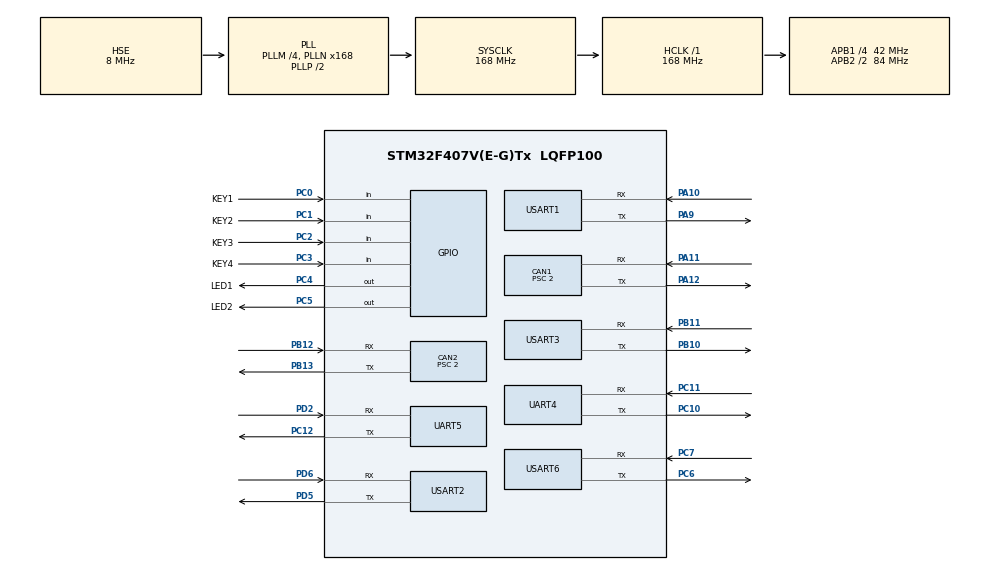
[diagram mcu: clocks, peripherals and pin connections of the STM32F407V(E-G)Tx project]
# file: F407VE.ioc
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CAN1.BS1=CAN_BS1_12TQ
CAN1.BS2=CAN_BS2_8TQ
CAN1.CalculateBaudRate=1000000
CAN1.CalculateTimeBit=1000
CAN1.CalculateTimeQuantum=47.61904761904762
CAN1.Prescaler=2
CAN1.SJW=CAN_SJW_1TQ
CAN2.BS1=CAN_BS1_12TQ
CAN2.BS2=CAN_BS2_8TQ
CAN2.CalculateBaudRate=1000000
CAN2.CalculateTimeBit=1000
CAN2.CalculateTimeQuantum=47.61904761904762
CAN2.Prescaler=2
CAN2.SJW=CAN_SJW_1TQ
Dma.Request0=USART3_RX
Dma.Request1=UART5_RX
Dma.Request2=USART3_TX
Dma.Request3=USART6_RX
Dma.Request4=USART1_RX
Dma.Request5=USART2_RX
Dma.Request6=UART4_RX
Dma.UART4_RX.6.Direction=DMA_PERIPH_TO_MEMORY
Dma.UART4_RX.6.FIFOMode=DMA_FIFOMODE_DISABLE
Dma.UART4_RX.6.Instance=DMA1_Stream2
Dma.UART4_RX.6.MemDataAlignment=DMA_MDATAALIGN_BYTE
Dma.UART4_RX.6.MemInc=DMA_MINC_ENABLE
Dma.UART4_RX.6.Mode=DMA_NORMAL
Dma.UART4_RX.6.PeriphDataAlignment=DMA_PDATAALIGN_BYTE
Dma.UART4_RX.6.PeriphInc=DMA_PINC_DISABLE
Dma.UART4_RX.6.Priority=DMA_PRIORITY_LOW
Dma.UART5_RX.1.Direction=DMA_PERIPH_TO_MEMORY
Dma.UART5_RX.1.FIFOMode=DMA_FIFOMODE_DISABLE
Dma.UART5_RX.1.Instance=DMA1_Stream0
Dma.UART5_RX.1.MemDataAlignment=DMA_MDATAALIGN_BYTE
Dma.UART5_RX.1.MemInc=DMA_MINC_ENABLE
Dma.UART5_RX.1.Mode=DMA_NORMAL
Dma.UART5_RX.1.PeriphDataAlignment=DMA_PDATAALIGN_BYTE
Dma.UART5_RX.1.PeriphInc=DMA_PINC_DISABLE
Dma.UART5_RX.1.Priority=DMA_PRIORITY_LOW
Dma.USART1_RX.4.Direction=DMA_PERIPH_TO_MEMORY
Dma.USART1_RX.4.FIFOMode=DMA_FIFOMODE_DISABLE
Dma.USART1_RX.4.Instance=DMA2_Stream2
Dma.USART1_RX.4.MemDataAlignment=DMA_MDATAALIGN_BYTE
Dma.USART1_RX.4.MemInc=DMA_MINC_ENABLE
Dma.USART1_RX.4.Mode=DMA_NORMAL
Dma.USART1_RX.4.PeriphDataAlignment=DMA_PDATAALIGN_BYTE
Dma.USART1_RX.4.PeriphInc=DMA_PINC_DISABLE
Dma.USART1_RX.4.Priority=DMA_PRIORITY_LOW
Dma.USART2_RX.5.Direction=DMA_PERIPH_TO_MEMORY
Dma.USART2_RX.5.FIFOMode=DMA_FIFOMODE_DISABLE
Dma.USART2_RX.5.Instance=DMA1_Stream5
Dma.USART2_RX.5.MemDataAlignment=DMA_MDATAALIGN_BYTE
Dma.USART2_RX.5.MemInc=DMA_MINC_ENABLE
Dma.USART2_RX.5.Mode=DMA_NORMAL
Dma.USART2_RX.5.PeriphDataAlignment=DMA_PDATAALIGN_BYTE
Dma.USART2_RX.5.PeriphInc=DMA_PINC_DISABLE
Dma.USART2_RX.5.Priority=DMA_PRIORITY_LOW
Dma.USART3_RX.0.Direction=DMA_PERIPH_TO_MEMORY
Dma.USART3_RX.0.FIFOMode=DMA_FIFOMODE_DISABLE
Dma.USART3_RX.0.Instance=DMA1_Stream1
Dma.USART3_RX.0.MemDataAlignment=DMA_MDATAALIGN_BYTE
Dma.USART3_RX.0.MemInc=DMA_MINC_ENABLE
Dma.USART3_RX.0.Mode=DMA_NORMAL
Dma.USART3_RX.0.PeriphDataAlignment=DMA_PDATAALIGN_BYTE
Dma.USART3_RX.0.PeriphInc=DMA_PINC_DISABLE
Dma.USART3_RX.0.Priority=DMA_PRIORITY_LOW
Dma.USART3_TX.2.Direction=DMA_MEMORY_TO_PERIPH
Dma.USART3_TX.2.FIFOMode=DMA_FIFOMODE_DISABLE
Dma.USART3_TX.2.Instance=DMA1_Stream3
Dma.USART3_TX.2.MemDataAlignment=DMA_MDATAALIGN_BYTE
Dma.USART3_TX.2.MemInc=DMA_MINC_ENABLE
Dma.USART3_TX.2.Mode=DMA_NORMAL
Dma.USART3_TX.2.PeriphDataAlignment=DMA_PDATAALIGN_BYTE
Dma.USART3_TX.2.PeriphInc=DMA_PINC_DISABLE
Dma.USART3_TX.2.Priority=DMA_PRIORITY_LOW
Dma.USART6_RX.3.Direction=DMA_PERIPH_TO_MEMORY
Dma.USART6_RX.3.FIFOMode=DMA_FIFOMODE_DISABLE
Dma.USART6_RX.3.Instance=DMA2_Stream1
Dma.USART6_RX.3.MemDataAlignment=DMA_MDATAALIGN_BYTE
Dma.USART6_RX.3.MemInc=DMA_MINC_ENABLE
Dma.USART6_RX.3.Mode=DMA_NORMAL
Dma.USART6_RX.3.PeriphDataAlignment=DMA_PDATAALIGN_BYTE
Dma.USART6_RX.3.PeriphInc=DMA_PINC_DISABLE
Dma.USART6_RX.3.Priority=DMA_PRIORITY_LOW
FREERTOS.Tasks01=defaultTask,24,128,StartDefaultTask,Default,NULL,Dynamic,NULL,NULL
FREERTOS.configTOTAL_HEAP_SIZE=16384
Mcu.Family=STM32F4
Mcu.Name=STM32F407V(E-G)Tx
Mcu.Package=LQFP100
NVIC.CAN1_RX0_IRQn=true\:5\:0\:false\:false\:true\:true\:true\:true\:true
NVIC.CAN1_RX1_IRQn=true\:5\:0\:false\:false\:true\:true\:true\:true\:true
NVIC.CAN2_RX0_IRQn=true\:5\:0\:false\:false\:true\:true\:true\:true\:true
NVIC.CAN2_RX1_IRQn=true\:5\:0\:false\:false\:true\:true\:true\:true\:true
NVIC.DMA1_Stream0_IRQn=true\:5\:0\:false\:false\:true\:true\:false\:true\:true
NVIC.DMA1_Stream1_IRQn=true\:5\:0\:false\:false\:true\:true\:false\:true\:true
NVIC.DMA1_Stream2_IRQn=true\:5\:0\:false\:false\:true\:true\:false\:true\:true
NVIC.DMA1_Stream3_IRQn=true\:5\:0\:false\:false\:true\:true\:false\:true\:true
NVIC.DMA1_Stream5_IRQn=true\:5\:0\:false\:false\:true\:true\:false\:true\:true
NVIC.DMA2_Stream1_IRQn=true\:5\:0\:false\:false\:true\:true\:false\:true\:true
NVIC.DMA2_Stream2_IRQn=true\:5\:0\:false\:false\:true\:true\:false\:true\:true
NVIC.PriorityGroup=NVIC_PRIORITYGROUP_4
NVIC.TIM3_IRQn=true\:5\:0\:false\:false\:true\:true\:true\:true\:true
NVIC.TIM8_TRG_COM_TIM14_IRQn=true\:15\:0\:false\:false\:true\:false\:false\:true\:true
NVIC.TimeBase=TIM8_TRG_COM_TIM14_IRQn
NVIC.TimeBaseIP=TIM14
NVIC.UART4_IRQn=true\:5\:0\:false\:false\:true\:true\:true\:true\:true
NVIC.UART5_IRQn=true\:5\:0\:false\:false\:true\:true\:true\:true\:true
NVIC.USART1_IRQn=true\:5\:0\:false\:false\:true\:true\:true\:true\:true
NVIC.USART2_IRQn=true\:5\:0\:false\:false\:true\:true\:true\:true\:true
NVIC.USART3_IRQn=true\:5\:0\:false\:false\:true\:true\:true\:true\:true
NVIC.USART6_IRQn=true\:5\:0\:false\:false\:true\:true\:true\:true\:true
PA10.Mode=Asynchronous
PA10.Signal=USART1_RX
PA11.Mode=CAN_Activate
PA11.Signal=CAN1_RX
PA12.Mode=CAN_Activate
PA12.Signal=CAN1_TX
PA13.Mode=Serial_Wire
PA13.Signal=SYS_JTMS-SWDIO
PA14.Mode=Serial_Wire
PA14.Signal=SYS_JTCK-SWCLK
PA9.Mode=Asynchronous
PA9.Signal=USART1_TX
PB10.Mode=Asynchronous
PB10.Signal=USART3_TX
PB11.Mode=Asynchronous
PB11.Signal=USART3_RX
PB12.Mode=CAN_Activate
PB12.Signal=CAN2_RX
PB13.Mode=CAN_Activate
PB13.Signal=CAN2_TX
PC0.GPIO_Label=KEY1
PC0.GPIO_PuPd=GPIO_PULLUP
PC0.Signal=GPIO_Input
PC1.GPIO_Label=KEY2
PC1.GPIO_PuPd=GPIO_PULLUP
PC1.Signal=GPIO_Input
PC10.Mode=Asynchronous
PC10.Signal=UART4_TX
PC11.Mode=Asynchronous
PC11.Signal=UART4_RX
PC12.Mode=Asynchronous
PC12.Signal=UART5_TX
PC2.GPIO_Label=KEY3
PC2.GPIO_PuPd=GPIO_PULLUP
PC2.Signal=GPIO_Input
PC3.GPIO_Label=KEY4
PC3.GPIO_PuPd=GPIO_PULLUP
PC3.Signal=GPIO_Input
PC4.GPIO_Label=LED1
PC4.PinState=GPIO_PIN_SET
PC4.Signal=GPIO_Output
PC5.GPIO_Label=LED2
PC5.PinState=GPIO_PIN_SET
PC5.Signal=GPIO_Output
PC6.Mode=Asynchronous
PC6.Signal=USART6_TX
PC7.Mode=Asynchronous
PC7.Signal=USART6_RX
PD2.Mode=Asynchronous
PD2.Signal=UART5_RX
PD5.Mode=Asynchronous
PD5.Signal=USART2_TX
PD6.Mode=Asynchronous
PD6.Signal=USART2_RX
PH0-OSC_IN.Mode=HSE-External-Oscillator
PH0-OSC_IN.Signal=RCC_OSC_IN
PH1-OSC_OUT.Mode=HSE-External-Oscillator
PH1-OSC_OUT.Signal=RCC_OSC_OUT
ProjectManager.HeapSize=0x400
ProjectManager.StackSize=0x400
ProjectManager.TargetToolchain=MDK-ARM V5.32
RCC.48MHZClocksFreq_Value=84000000
RCC.AHBFreq_Value=168000000
RCC.APB1CLKDivider=RCC_HCLK_DIV4
RCC.APB1Freq_Value=42000000
RCC.APB1TimFreq_Value=84000000
RCC.APB2CLKDivider=RCC_HCLK_DIV2
RCC.APB2Freq_Value=84000000
RCC.APB2TimFreq_Value=168000000
RCC.CortexFreq_Value=168000000
RCC.HCLKFreq_Value=168000000
RCC.HSE_VALUE=8000000
RCC.HSI_VALUE=16000000
RCC.LSE_VALUE=32768
RCC.PLLM=4
RCC.PLLN=168
RCC.PLLSourceVirtual=RCC_PLLSOURCE_HSE
RCC.SYSCLKFreq_VALUE=168000000
RCC.SYSCLKSource=RCC_SYSCLKSOURCE_PLLCLK
RCC.VCOOutputFreq_Value=336000000
TIM3.Period=99
TIM3.Prescaler=8399
UART4.VirtualMode=Asynchronous
UART5.VirtualMode=Asynchronous
USART1.VirtualMode=VM_ASYNC
USART2.VirtualMode=VM_ASYNC
USART3.VirtualMode=VM_ASYNC
USART6.VirtualMode=VM_ASYNC
VP_FREERTOS_VS_CMSIS_V2.Mode=CMSIS_V2
VP_SYS_VS_tim14.Mode=TIM14
VP_TIM3_VS_ClockSourceINT.Mode=Internal
board=custom

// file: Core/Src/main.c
/* USER CODE BEGIN Header */
/**
  ******************************************************************************
  * @file           : main.c
  * @brief          : Main program body
  ******************************************************************************
  * @attention
  *
  * Copyright (c) 2025 STMicroelectronics.
  * All rights reserved.
  *
  * This software is licensed under terms that can be found in the LICENSE file
  * in the root directory of this software component.
  * If no LICENSE file comes with this software, it is provided AS-IS.
  *
  ******************************************************************************
  */
/* USER CODE END Header */
#include "main.h"
#include "cmsis_os.h"
#include "can.h"
#include "dma.h"
#include "tim.h"
#include "usart.h"
#include "gpio.h"

void SystemClock_Config(void);
void MX_FREERTOS_Init(void);

int main(void)
{

  /* MCU Configuration--------------------------------------------------------*/

  /* Reset of all peripherals, Initializes the Flash interface and the Systick. */
  HAL_Init();

  /* Configure the system clock */
  SystemClock_Config();

  /* Initialize all configured peripherals */
  MX_GPIO_Init();
  MX_DMA_Init();
  MX_CAN1_Init();
  MX_UART5_Init();
  MX_USART3_UART_Init();
  MX_TIM3_Init();
  MX_USART6_UART_Init();
  MX_USART1_UART_Init();
  MX_USART2_UART_Init();
  MX_UART4_Init();
  MX_CAN2_Init();

  /* Init scheduler */
  osKernelInitialize();

  /* Call init function for freertos objects (in cmsis_os2.c) */
  MX_FREERTOS_Init();

  /* Start scheduler */
  osKernelStart();

  /* We should never get here as control is now taken by the scheduler */

  /* Infinite loop */
  while (1)
  {

  }
}

void SystemClock_Config(void)
{
  RCC_OscInitTypeDef RCC_OscInitStruct = {0};
  RCC_ClkInitTypeDef RCC_ClkInitStruct = {0};

  /** Configure the main internal regulator output voltage
  */
  __HAL_RCC_PWR_CLK_ENABLE();
  __HAL_PWR_VOLTAGESCALING_CONFIG(PWR_REGULATOR_VOLTAGE_SCALE1);

  /** Initializes the RCC Oscillators according to the specified parameters
  * in the RCC_OscInitTypeDef structure.
  */
  RCC_OscInitStruct.OscillatorType = RCC_OSCILLATORTYPE_HSE;
  RCC_OscInitStruct.HSEState = RCC_HSE_ON;
  RCC_OscInitStruct.PLL.PLLState = RCC_PLL_ON;
  RCC_OscInitStruct.PLL.PLLSource = RCC_PLLSOURCE_HSE;
  RCC_OscInitStruct.PLL.PLLM = 4;
  RCC_OscInitStruct.PLL.PLLN = 168;
  RCC_OscInitStruct.PLL.PLLP = RCC_PLLP_DIV2;
  RCC_OscInitStruct.PLL.PLLQ = 4;
  if (HAL_RCC_OscConfig(&RCC_OscInitStruct) != HAL_OK)
  {
    Error_Handler();
  }

  /** Initializes the CPU, AHB and APB buses clocks
  */
  RCC_ClkInitStruct.ClockType = RCC_CLOCKTYPE_HCLK|RCC_CLOCKTYPE_SYSCLK
                              |RCC_CLOCKTYPE_PCLK1|RCC_CLOCKTYPE_PCLK2;
  RCC_ClkInitStruct.SYSCLKSource = RCC_SYSCLKSOURCE_PLLCLK;
  RCC_ClkInitStruct.AHBCLKDivider = RCC_SYSCLK_DIV1;
  RCC_ClkInitStruct.APB1CLKDivider = RCC_HCLK_DIV4;
  RCC_ClkInitStruct.APB2CLKDivider = RCC_HCLK_DIV2;

  if (HAL_RCC_ClockConfig(&RCC_ClkInitStruct, FLASH_LATENCY_5) != HAL_OK)
  {
    Error_Handler();
  }
}

void HAL_TIM_PeriodElapsedCallback(TIM_HandleTypeDef *htim)
{
  if (htim->Instance == TIM14) {
    HAL_IncTick();
  }
}

void Error_Handler(void)
{
  __disable_irq();
  while (1)
  {
  }
}

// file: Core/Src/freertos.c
/* USER CODE BEGIN Header */
/**
  ******************************************************************************
  * File Name          : freertos.c
  * Description        : Code for freertos applications
  ******************************************************************************
  * @attention
  *
  * Copyright (c) 2025 STMicroelectronics.
  * All rights reserved.
  *
  * This software is licensed under terms that can be found in the LICENSE file
  * in the root directory of this software component.
  * If no LICENSE file comes with this software, it is provided AS-IS.
  *
  ******************************************************************************
  */
  /* USER CODE END Header */

  /* Includes ------------------------------------------------------------------*/
#include "FreeRTOS.h"
#include "task.h"
#include "main.h"
#include "cmsis_os.h"

/* USER CODE BEGIN Includes */
#include "common_inc.h"

/* USER CODE END Includes */

/* Definitions for defaultTask */
osThreadId_t defaultTaskHandle;
const osThreadAttr_t defaultTask_attributes = {
  .name = "defaultTask",
  .stack_size = 128 * 4,
  .priority = (osPriority_t)osPriorityNormal,
};

void StartDefaultTask(void* argument);

void MX_FREERTOS_Init(void); /* (MISRA C 2004 rule 8.1) */

void MX_FREERTOS_Init(void) {

    /* Create the thread(s) */
    /* creation of defaultTask */
    defaultTaskHandle = osThreadNew(StartDefaultTask, NULL, &defaultTask_attributes);

}

void StartDefaultTask(void* argument)
{
    /* USER CODE BEGIN StartDefaultTask */
    taskENTER_CRITICAL();
    Main();
    vTaskDelete(defaultTaskHandle);
    taskEXIT_CRITICAL();
    /* USER CODE END StartDefaultTask */
}
